# ATSAM4C32E_0 register map
Vendor: Atmel; Series: SAM4C; File version: 0
CPU: CM4 r0p0, selectable endian, MPU, no FPU, 4 interrupt priority bits
Registers are 32-bit, read-write, reset 0x0 unless marked. A register's access mark holds for its fields unless they carry their own. Offsets are from the block's base; [hi:lo] are bit positions; {n}, {i} and the like mark numbered series; 'fields as' and 'values as' point back to an identical list.

## PIOA — Parallel Input/Output Controller A
Base 0x400E0E00; register names take the prefix PIOA_
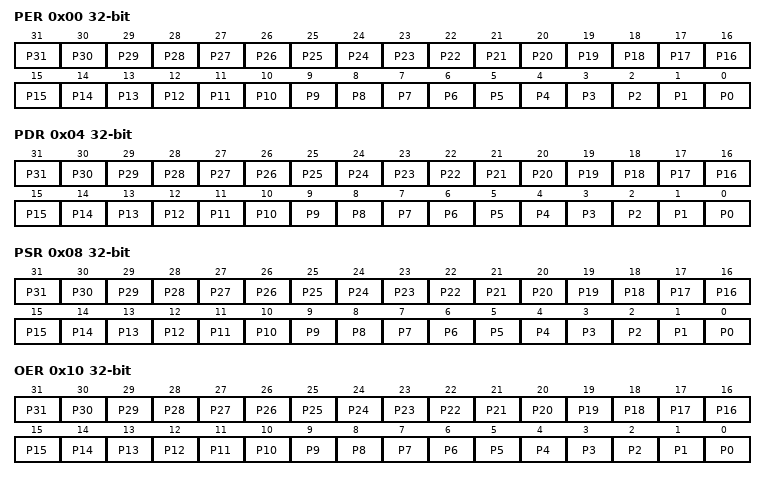
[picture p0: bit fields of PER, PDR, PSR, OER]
0x00 PER wo reset not defined — PIO Enable Register
  [n] P{n} (n=0..31) — PIO Enable
0x04 PDR wo reset not defined — PIO Disable Register
  [n] P{n} (n=0..31) — PIO Disable
0x08 PSR ro reset not defined — PIO Status Register
  [n] P{n} (n=0..31) — PIO Status
0x10 OER wo reset not defined — Output Enable Register
  [n] P{n} (n=0..31) — Output Enable
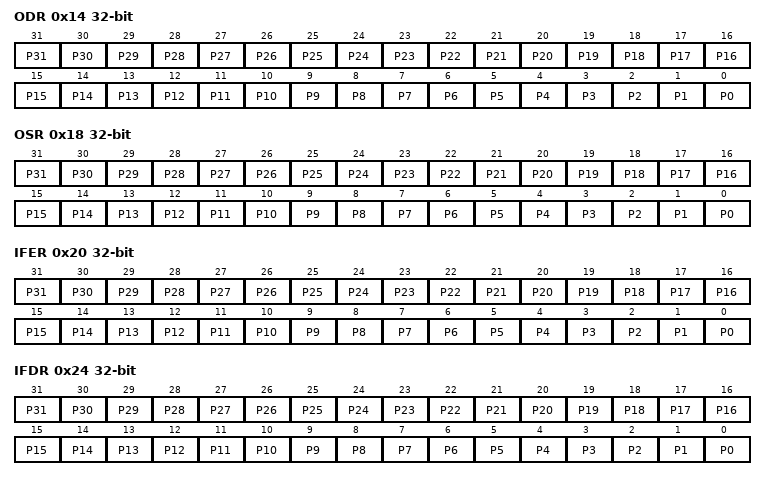
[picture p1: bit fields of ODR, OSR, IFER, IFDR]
0x14 ODR wo reset not defined — Output Disable Register
  [n] P{n} (n=0..31) — Output Disable
0x18 OSR ro — Output Status Register
  [n] P{n} (n=0..31) — Output Status
0x20 IFER wo reset not defined — Glitch Input Filter Enable Register
  [n] P{n} (n=0..31) — Input Filter Enable
0x24 IFDR wo reset not defined — Glitch Input Filter Disable Register
  [n] P{n} (n=0..31) — Input Filter Disable
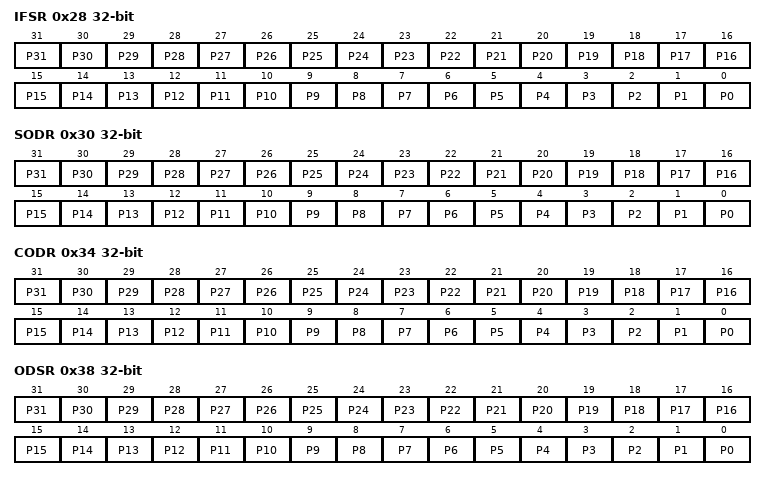
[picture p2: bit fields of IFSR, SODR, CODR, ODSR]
0x28 IFSR ro — Glitch Input Filter Status Register
  [n] P{n} (n=0..31) — Input Filer Status
0x30 SODR wo reset not defined — Set Output Data Register
  [n] P{n} (n=0..31) — Set Output Data
0x34 CODR wo reset not defined — Clear Output Data Register
  [n] P{n} (n=0..31) — Clear Output Data
0x38 ODSR reset not defined — Output Data Status Register
  [n] P{n} (n=0..31) — Output Data Status
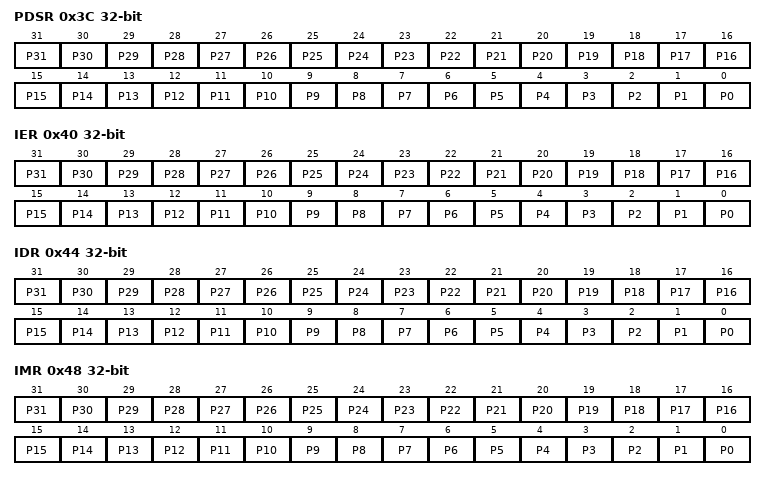
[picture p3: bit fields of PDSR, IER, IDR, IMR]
0x3C PDSR ro reset not defined — Pin Data Status Register
  [n] P{n} (n=0..31) — Output Data Status
0x40 IER wo reset not defined — Interrupt Enable Register
  [n] P{n} (n=0..31) — Input Change Interrupt Enable
0x44 IDR wo reset not defined — Interrupt Disable Register
  [n] P{n} (n=0..31) — Input Change Interrupt Disable
0x48 IMR ro — Interrupt Mask Register
  [n] P{n} (n=0..31) — Input Change Interrupt Mask
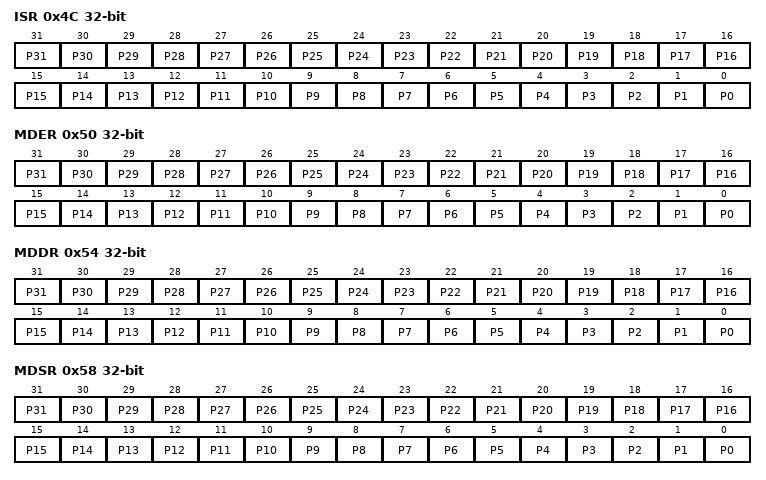
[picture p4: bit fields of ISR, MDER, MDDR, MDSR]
0x4C ISR ro — Interrupt Status Register
  [n] P{n} (n=0..31) — Input Change Interrupt Status
0x50 MDER wo reset not defined — Multi-driver Enable Register
  [n] P{n} (n=0..31) — Multi-Drive Enable
0x54 MDDR wo reset not defined — Multi-driver Disable Register
  [n] P{n} (n=0..31) — Multi-Drive Disable
0x58 MDSR ro — Multi-driver Status Register
  [n] P{n} (n=0..31) — Multi-Drive Status
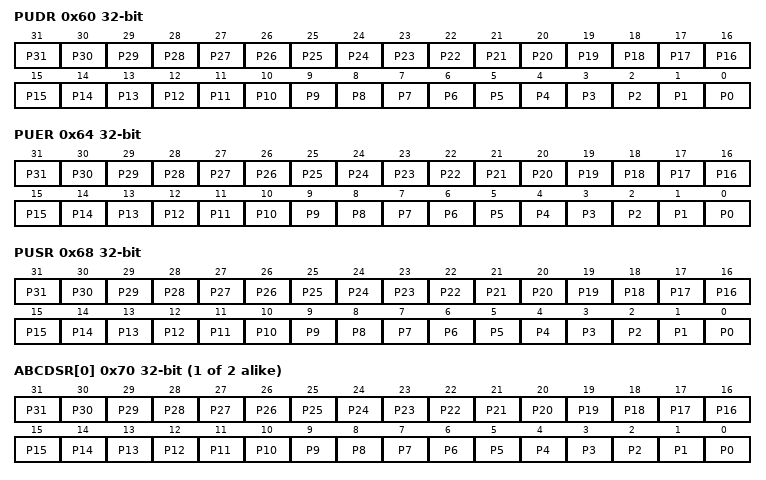
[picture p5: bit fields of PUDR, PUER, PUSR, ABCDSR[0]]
0x60 PUDR wo reset not defined — Pull-up Disable Register
  [n] P{n} (n=0..31) — Pull-Up Disable
0x64 PUER wo reset not defined — Pull-up Enable Register
  [n] P{n} (n=0..31) — Pull-Up Enable
0x68 PUSR ro reset not defined — Pad Pull-up Status Register
  [n] P{n} (n=0..31) — Pull-Up Status
{0x70+4i} ABCDSR[{i}] (i=0..1) reset not defined — Peripheral Select Register
  [n] P{n} (n=0..31) — Peripheral Select
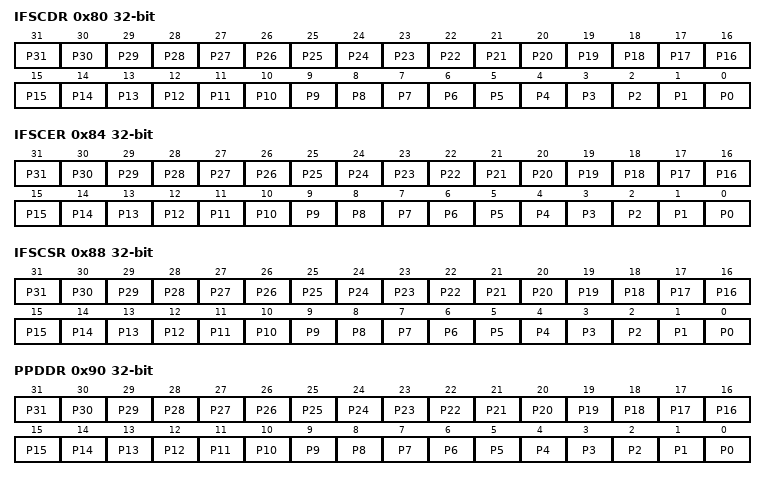
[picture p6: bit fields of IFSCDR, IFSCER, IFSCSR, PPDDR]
0x80 IFSCDR wo reset not defined — Input Filter Slow Clock Disable Register
  [n] P{n} (n=0..31) — PIO Clock Glitch Filtering Select
0x84 IFSCER wo reset not defined — Input Filter Slow Clock Enable Register
  [n] P{n} (n=0..31) — Debouncing Filtering Select
0x88 IFSCSR ro — Input Filter Slow Clock Status Register
  [n] P{n} (n=0..31) — Glitch or Debouncing Filter Selection Status
0x8C SCDR — Slow Clock Divider Debouncing Register
  [13:0] DIV — Slow Clock Divider Selection for Debouncing
0x90 PPDDR wo reset not defined — Pad Pull-down Disable Register
  [n] P{n} (n=0..31) — Pull-Down Disable
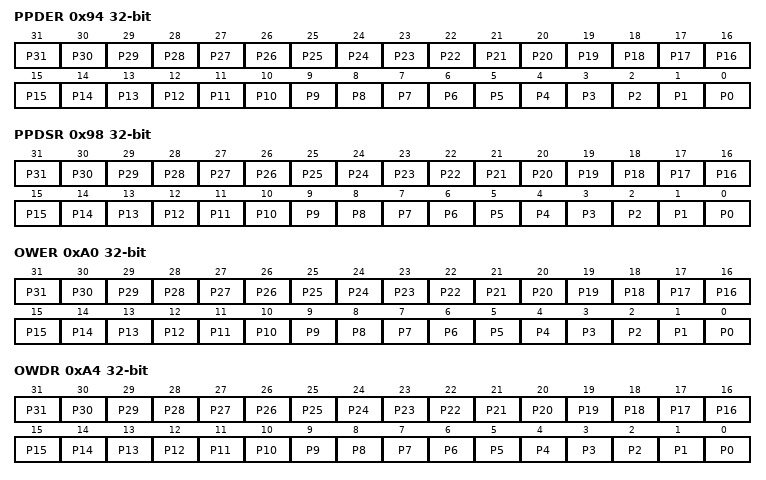
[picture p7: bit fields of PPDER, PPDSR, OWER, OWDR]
0x94 PPDER wo reset not defined — Pad Pull-down Enable Register
  [n] P{n} (n=0..31) — Pull-Down Enable
0x98 PPDSR ro reset not defined — Pad Pull-down Status Register
  [n] P{n} (n=0..31) — Pull-Down Status
0xA0 OWER wo reset not defined — Output Write Enable
  [n] P{n} (n=0..31) — Output Write Enable
0xA4 OWDR wo reset not defined — Output Write Disable
  [n] P{n} (n=0..31) — Output Write Disable
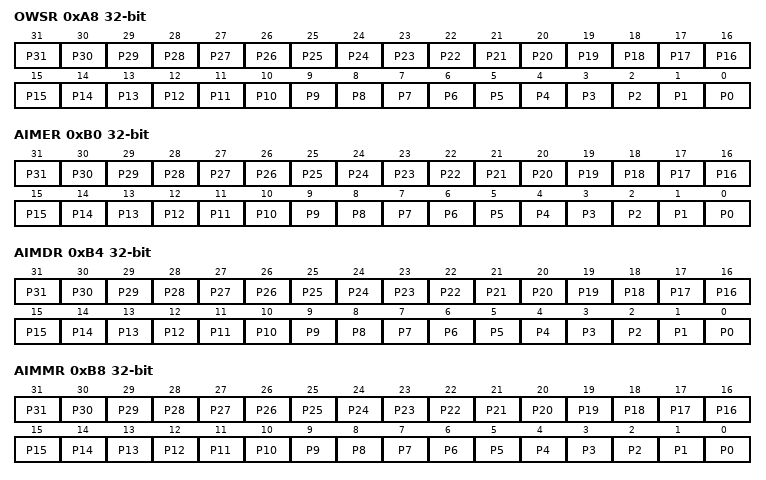
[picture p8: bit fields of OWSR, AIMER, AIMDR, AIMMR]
0xA8 OWSR ro — Output Write Status Register
  [n] P{n} (n=0..31) — Output Write Status
0xB0 AIMER wo reset not defined — Additional Interrupt Modes Enable Register
  [n] P{n} (n=0..31) — Additional Interrupt Modes Enable
0xB4 AIMDR wo reset not defined — Additional Interrupt Modes Disable Register
  [n] P{n} (n=0..31) — Additional Interrupt Modes Disable
0xB8 AIMMR ro — Additional Interrupt Modes Mask Register
  [n] P{n} (n=0..31) — Peripheral CD Status
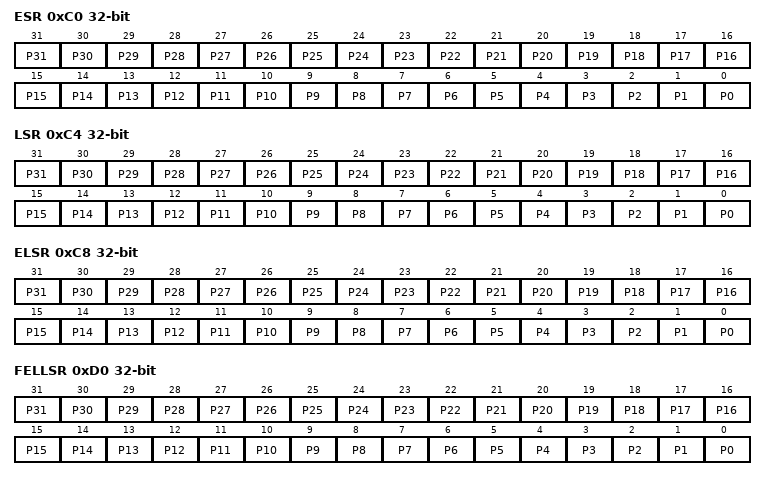
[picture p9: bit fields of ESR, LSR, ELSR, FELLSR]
0xC0 ESR wo reset not defined — Edge Select Register
  [n] P{n} (n=0..31) — Edge Interrupt Selection
0xC4 LSR wo reset not defined — Level Select Register
  [n] P{n} (n=0..31) — Level Interrupt Selection
0xC8 ELSR ro — Edge/Level Status Register
  [n] P{n} (n=0..31) — Edge/Level Interrupt Source Selection
0xD0 FELLSR wo reset not defined — Falling Edge/Low-Level Select Register
  [n] P{n} (n=0..31) — Falling Edge/Low-Level Interrupt Selection
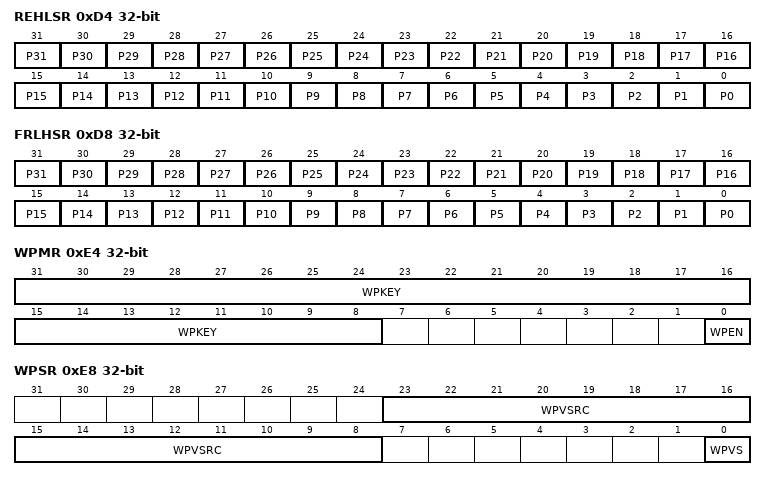
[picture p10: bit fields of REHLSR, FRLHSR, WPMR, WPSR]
0xD4 REHLSR wo reset not defined — Rising Edge/ High-Level Select Register
  [n] P{n} (n=0..31) — Rising Edge /High-Level Interrupt Selection
0xD8 FRLHSR ro — Fall/Rise - Low/High Status Register
  [n] P{n} (n=0..31) — Edge /Level Interrupt Source Selection
0xE4 WPMR — Write Protection Mode Register
  [31:8] WPKEY — Write Protection Key.
    0x50494F=PASSWD (Writing any other value in this field aborts the write operation of the WPEN bit. Always reads as 0.)
  [0] WPEN — Write Protection Enable
0xE8 WPSR ro — Write Protection Status Register
  [23:8] WPVSRC — Write Protection Violation Source
  [0] WPVS — Write Protection Violation Status
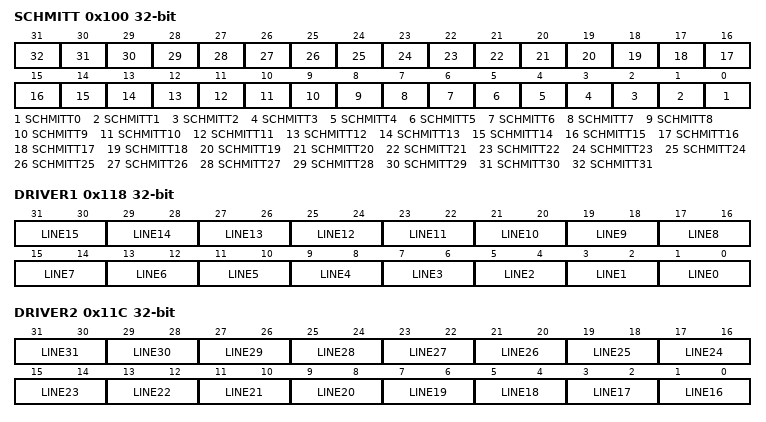
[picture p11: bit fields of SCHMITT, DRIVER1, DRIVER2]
0x100 SCHMITT — Schmitt Trigger Register
  [n] SCHMITT{n} (n=0..31) — Schmitt Trigger Control
0x118 DRIVER1 — I/O Drive Register 1
  [all] fields
    0=HI_DRIVE (High drive); 1=ME_DRIVE (Medium drive); 2=LO_DRIVE (Low drive)
  [2n+1:2n] LINE{n} (n=0..15) — Drive of PIO Line {n}
0x11C DRIVER2 — I/O Drive Register 2
  [all] fields
    values as the fields of DRIVER1
  [2n-31:2n-32] LINE{n} (n=16..31) — Drive of PIO line {n}

## PIOB — Parallel Input/Output Controller B
Base 0x400E1000; register names take the prefix PIOB_
Registers as PIOA.

## PIOD — Parallel Input/Output Controller D
Base 0x400E1200; register names take the prefix PIOD_
Registers as PIOA.

## PIOC — Parallel Input/Output Controller C
Base 0x4800C000; register names take the prefix PIOC_
Registers as PIOA.

## Notices in the file
SAM Software Package License
Copyright (c) 2014, Atmel Corporation
All rights reserved.
Redistribution and use in source and binary forms, with or without
modification, are permitted provided that the following condition is met:
- Redistributions of source code must retain the above copyright notice,
this list of conditions and the disclaimer below.
Atmel's name may not be used to endorse or promote products derived from
this software without specific prior written permission.
DISCLAIMER:  THIS SOFTWARE IS PROVIDED BY ATMEL "AS IS" AND ANY EXPRESS OR
IMPLIED WARRANTIES, INCLUDING, BUT NOT LIMITED TO, THE IMPLIED WARRANTIES OF
MERCHANTABILITY, FITNESS FOR A PARTICULAR PURPOSE AND NON-INFRINGEMENT ARE
DISCLAIMED. IN NO EVENT SHALL ATMEL BE LIABLE FOR ANY DIRECT, INDIRECT,
INCIDENTAL, SPECIAL, EXEMPLARY, OR CONSEQUENTIAL DAMAGES (INCLUDING, BUT NOT
LIMITED TO, PROCUREMENT OF SUBSTITUTE GOODS OR SERVICES; LOSS OF USE, DATA,
OR PROFITS; OR BUSINESS INTERRUPTION) HOWEVER CAUSED AND ON ANY THEORY OF
LIABILITY, WHETHER IN CONTRACT, STRICT LIABILITY, OR TORT (INCLUDING
NEGLIGENCE OR OTHERWISE) ARISING IN ANY WAY OUT OF THE USE OF THIS SOFTWARE,
EVEN IF ADVISED OF THE POSSIBILITY OF SUCH DAMAGE.
